# haltium_secure register map
Vendor: Nordic Semiconductor; Series: nRFHaltium; File version: 1
CPU: CM33 r0p4, little endian, MPU, FPU, 3 interrupt priority bits, 480 interrupts
Registers are 32-bit, read-write, reset 0x0 unless marked. A register's access mark holds for its fields unless they carry their own. Offsets are from the block's base; [hi:lo] are bit positions; {n}, {i} and the like mark numbered series; 'fields as' and 'values as' point back to an identical list.

## RAMC000_NS — RAM Controller 0
Base 0x41004000
Same registers: RAMC001_NS 0x41007000, RAMC000_S 0x51004000, RAMC001_S 0x51007000
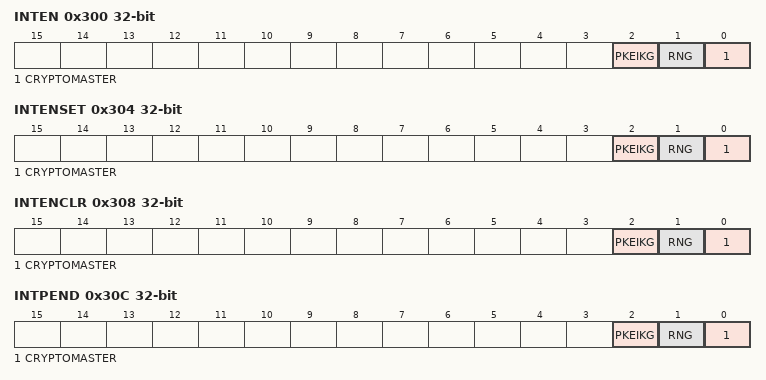
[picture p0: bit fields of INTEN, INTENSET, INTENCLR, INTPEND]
0x300 INTEN — Enable or disable interrupt
0x304 INTENSET — Enable interrupt
0x308 INTENCLR — Disable interrupt
0x500 WAITSTATES — Waitstates for read.
  [2:0] WAITSTATES — Waitstates for read from RAM or ROM.
0x600 SECBASE — Base address for secure access area.
  [31:0] ADDR — Base address
0x604 SECENABLE — Enable secure access restrictions.
  [0] ENABLE — Enable secure access restrictions
    0=Disable (Secure access restrictions disabled); 1=Enable (Secure access restrictions enabled)

## ROMC_NS — ROM Controller 0
Base 0x41005000
Same registers: ROMC_S 0x51005000

## CRACEN_NS — CRACEN 0
Base 0x41006000
Same registers: CRACEN_S 0x51006000
0x100 EVENTS_CRYPTOMASTER — Event indicating that interrupt triggered at Cryptomaaster
  [0] EVENTS_CRYPTOMASTER
    0=NotGenerated (Event not generated); 1=Generated (Event generated)
0x104 EVENTS_RNG — Event indicating that interrupt triggered at RNG
  [0] EVENTS_RNG
    values as EVENTS_CRYPTOMASTER.EVENTS_CRYPTOMASTER
0x108 EVENTS_PKEIKG — Event indicating that interrupt triggered at PKE or IKG
  [0] EVENTS_PKEIKG
    values as EVENTS_CRYPTOMASTER.EVENTS_CRYPTOMASTER
0x300 INTEN — Enable or disable interrupt
  [all] fields
    0=Disabled; 1=Enabled
  [2] PKEIKG — Enable or disable interrupt for event PKEIKG
  [1] RNG — Enable or disable interrupt for event RNG
  [0] CRYPTOMASTER — Enable or disable interrupt for event CRYPTOMASTER
0x304 INTENSET — Enable interrupt
  [all] fields
    on read: 0=Disabled (Read: Disabled); 1=Enabled (Read: Enabled) | on write: 1=Set (Enable)
  [2] PKEIKG — Write '1' to enable interrupt for event PKEIKG
  [1] RNG — Write '1' to enable interrupt for event RNG
  [0] CRYPTOMASTER — Write '1' to enable interrupt for event CRYPTOMASTER
0x308 INTENCLR — Disable interrupt
  [all] fields
    on read: 0=Disabled (Read: Disabled); 1=Enabled (Read: Enabled) | on write: 1=Clear (Disable)
  [2] PKEIKG — Write '1' to disable interrupt for event PKEIKG
  [1] RNG — Write '1' to disable interrupt for event RNG
  [0] CRYPTOMASTER — Write '1' to disable interrupt for event CRYPTOMASTER
0x30C INTPEND ro — Pending interrupts
  [all] fields
    on read: 0=NotPending (Read: Not pending); 1=Pending (Read: Pending)
  [2] PKEIKG — Read pending status of interrupt for event PKEIKG
  [1] RNG — Read pending status of interrupt for event RNG
  [0] CRYPTOMASTER — Read pending status of interrupt for event CRYPTOMASTER
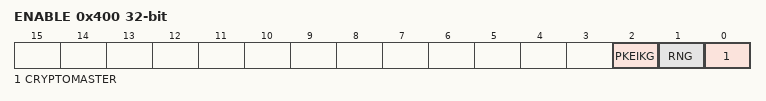
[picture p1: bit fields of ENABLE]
0x400 ENABLE — Enable CRACEN peripheral modules.
  [2] PKEIKG — Enable PKE and IKG
    0=Disabled (PKE and IKG disabled.); 1=Enabled (PKE and IKG enabled.)
  [1] RNG — Enable RNG
    0=Disabled (RNG disabled.); 1=Enabled (RNG enabled.)
  [0] CRYPTOMASTER — Enable cryptomaster
    0=Disabled (Cryptomaster disabled.); 1=Enabled (Cryptomaster enabled.)
0x404 KEYLOCK — Lock the accesses to RAM used for key
  [0] ENABLE — Enable the lock
    0=Disabled (Lock disabled.); 1=Enabled (Lock enabled.)
{0x408+4i} SEED[{i}] (i=0..11) wo — Description collection: Seed word [n] for private key generation.
  [31:0] VAL — Seed value

## PCGCS000_S — PCGCSlave 0
Base 0x5100A000
Same registers: PCGCS010_S 0x5101C000
0x78 TRIGZEROPENALTY ro — Trigger zero penalty
  [0] TRIGGER
    1=Enable (Trigger zero penalty)
0x7C TRIGFULLPENALTY ro — Trigger full penalty
  [0] TRIGGER
    1=Enable (Trigger full penalty)
{0xC00+4i} PENALTY[{i}] (i=0..1) ro — Description collection: Penalty level for power/clock pair n
  [7:0] PENALTY — Penalty level
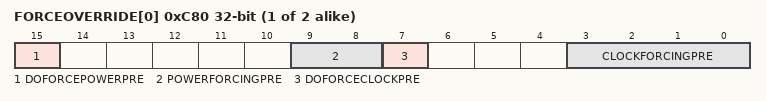
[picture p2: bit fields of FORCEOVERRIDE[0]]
{0xC80+4i} FORCEOVERRIDE[{i}] (i=0..1) ro — Description collection: Force override of power/clock pair n
  [15] DOFORCEPOWERPRE, [9:8] POWERFORCINGPRE, [7] DOFORCECLOCKPRE, [3:0] CLOCKFORCINGPRE
